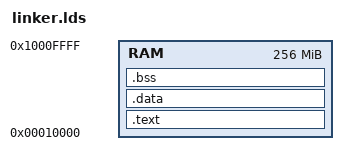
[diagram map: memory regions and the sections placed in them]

ENTRY(_start)

MEMORY
{
        /* RAM : ORIGIN = 0x00000800, LENGTH = 256M */
        RAM : ORIGIN = 0x00010000, LENGTH = 256M
}

SECTIONS
{
        /**********************************************************************
         *                                                                    *
         **********************************************************************/
        .text :
        {
                _stext = .;
                *(.startup)
                *(.text)
                *(.text.*)
                *(.rodata)
                *(.rodata.*)
                _etext = .;
                . = ALIGN(0x10);
        } > RAM
        /**********************************************************************
         *                                                                    *
         **********************************************************************/
        .data :
        {
                _sdata = .;
                *(.data)
                *(.data.*)
                *(.sdata)
                *(.sdata.*)
                _edata = .;
                . = ALIGN(0x1000);
        } > RAM
        /**********************************************************************
         *                                                                    *
         **********************************************************************/
        .bss (NOLOAD) :
        {
                _sbss = .;
                *(.bss)
                *(.bss.*)
                *(COMMON)
                . = ALIGN(0x10);
                _ebss = .;
        } > RAM
        /**********************************************************************
         *                                                                    *
         **********************************************************************/
        .debug_info     0 : { *(.debug_info) }
        .debug_abbrev   0 : { *(.debug_abbrev) }
        .debug_aranges  0 : { *(.debug_aranges) }
        .debug_frame    0 : { *(.debug_frame) }
        .debug_line     0 : { *(.debug_line) }
        .debug_line_str 0 : { *(.debug_line_str) }
        .debug_loclists 0 : { *(.debug_loclists) }
        .debug_macro    0 : { *(.debug_macro) }
        .debug_names    0 : { *(.debug_names) }
        .debug_rnglists 0 : { *(.debug_rnglists) }
        .debug_str      0 : { *(.debug_str) }
        /**********************************************************************
         *                                                                    *
         **********************************************************************/
        /DISCARD/ :
        {
                *(*)
        }
}

